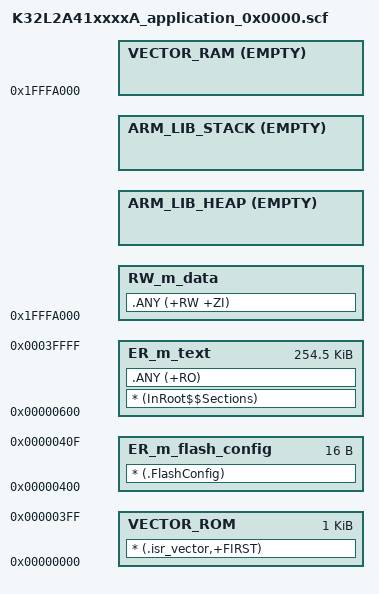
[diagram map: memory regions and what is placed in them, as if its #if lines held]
#!armclang --target=arm-arm-none-eabi -mcpu=cortex-m0plus -E -x c
/*
** ###################################################################
**     Processors:          K32L2A41VLH1A
**                          K32L2A41VLL1A
**
**     Compiler:            Keil ARM C/C++ Compiler
**     Reference manual:    K32L2AxRM, Rev. 0, Oct, 2019
**     Version:             rev. 1.0, 2019-10-30
**     Build:               b191118
**
**     Abstract:
**         Linker file for the Keil ARM C/C++ Compiler
**
**     Copyright 2016 Freescale Semiconductor, Inc.
**     Copyright 2016-2020 NXP
**     All rights reserved.
**
**     SPDX-License-Identifier: BSD-3-Clause
**
**     http:                 www.nxp.com
**     mail:                 support@nxp.com
**
** ###################################################################
*/


#define m_interrupts_start             0x00000000
#define m_interrupts_size              0x00000400

#define m_flash_config_start           0x00000400
#define m_flash_config_size            0x00000010

//#define m_text_start                   0x00000410
//#define m_text_size                    0x0003FBF0
#define m_text_start                   0x00000600
#define m_text_size                    0x0003FA00

#define m_interrupts_ram_start         0x1FFFA000
#define m_interrupts_ram_size          0x0

#define m_data_start                   (m_interrupts_ram_start + m_interrupts_ram_size)
#define m_data_size                    (0x00004000 - m_interrupts_ram_size)

#define m_data_2_start                 0x20000000
#define m_data_2_size                  0x00012000

/* Sizes */
#if (defined(__stack_size__))
  #define Stack_Size                   __stack_size__
#else
  #define Stack_Size                   0x1000
#endif

#if (defined(__heap_size__))
  #define Heap_Size                    __heap_size__
#else
  #define Heap_Size                    0x0
#endif

LR_m_text m_text_start m_text_size {   ; load region size_region
  ER_m_text m_text_start m_text_size { ; load address = execution address
    * (InRoot$$Sections)
    .ANY (+RO)
  }
  RW_m_data m_data_start m_data_size +  m_data_2_size-Stack_Size-Heap_Size{ ; RW data
    .ANY (+RW +ZI)
  }
  ARM_LIB_HEAP (ImageLimit(RW_m_data)) EMPTY Heap_Size { ; Heap region growing up
  }
  ARM_LIB_STACK (ImageLimit(ARM_LIB_HEAP) + Stack_Size) EMPTY -Stack_Size { ; Stack region growing down
  }
}

LR_m_interrupts m_interrupts_start m_interrupts_size {
  VECTOR_ROM m_interrupts_start m_interrupts_size { ; load address = execution address
    * (.isr_vector,+FIRST)
  }
}

LR_m_flash_config m_flash_config_start m_flash_config_size {
  ER_m_flash_config m_flash_config_start m_flash_config_size { ; load address = execution address
    * (.FlashConfig)
  }
}

LR_m_interrupts_ram m_interrupts_ram_start m_interrupts_ram_size {
  VECTOR_RAM m_interrupts_ram_start EMPTY m_interrupts_ram_size {
  }
}

